# K32W041AM register map
Vendor: nxp.com; File version: 1.0
CPU: CM4 r0p1, little endian, MPU, no FPU, VTOR, 3 interrupt priority bits
Registers are 32-bit, read-write, reset 0x0 unless marked. A register's access mark holds for its fields unless they carry their own. Offsets are from the block's base; [hi:lo] are bit positions.

## WWDT — This is the description of component wwdt It is an Windowed Watchdog Timer with APB bus interface. More details will follow.
Base 0x4000A000
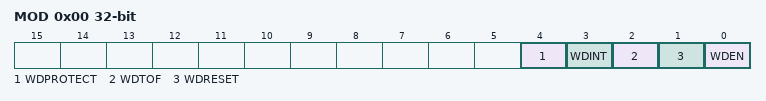
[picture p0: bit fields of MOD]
0x00 MOD — Watchdog mode register. This register contains the basic mode and status of the Watchdog Timer.
  [4] WDPROTECT — Watchdog update mode. This bit can be set once by software and is only cleared by a reset. 0: Flexible. A feed sequence can be performed at any time; ie. the watchdog timer can be reloaded with time-out value (TC) at any time. 1: Threshold. A feed sequence can be performed only after the counter is below the value of WDWARNINT and WDWINDOW; ie. the watchdog timer can be reloaded with time-out value (TC) only when the counter timer value is below the value of WDWARNINT and WDWINDOW, otherwise a 'feed error' is created.
  [3] WDINT — Warning interrupt flag. Set when the timer reaches the value in WDWARNINT. Cleared by software writing a 1 to this bit position. Note that this bit cannot be cleared while the WARNINT value is equal to the value of the TV register. This can occur if the value of WARNINT is 0 and the WDRESET bit is 0 when TV decrements to 0.
  [2] WDTOF — Watchdog time-out flag. Set when the watchdog timer times out, by a feed error, or by events associated with WDPROTECT. Cleared by software writing a 0 to this bit position. Causes a chip reset if WDRESET = 1.
  [1] WDRESET — Watchdog reset enable bit. Once this bit has been written with a 1 it cannot be re-written with a 0. 0: Interrupt. A watchdog time-out will not cause a chip reset. It will cause an interrupt of the watchdog. 1: Reset. A watchdog time-out will cause a chip reset.
  [0] WDEN — Watchdog enable bit. Once this bit is set to one and a watchdog feed is performed, the watchdog timer will run permanently. 0: The watchdog timer is stopped. 1: The watchdog timer is running.
0x04 TC reset 0xFF — Watchdog timer constant register. This 24-bit register determines the time-out value.
  [23:0] COUNT — Watchdog time-out value. If MOD.WDPROTECT is set then changing this value may cause an error.
0x08 FEED wo reset not defined — Watchdog feed sequence register. Writing 0xAA followed by 0x55 to this register reloads the Watchdog timer with the value contained in TC.
  [7:0] FEED — Feed value should be 0xAA followed by 0x55. Writing 0xAA followed by 0x55 to this register will reload the Watchdog timer with the TC value. This operation will also start the Watchdog if it is enabled via the WDMOD register. Setting the WDEN bit in the WDMOD register is not sufficient to enable the Watchdog. A valid feed sequence must be completed after setting WDEN before the Watchdog is capable of generating a reset. Until then, the Watchdog will ignore feed errors.
0x0C TV ro reset 0xFF — Watchdog timer value register. This 24-bit register reads out the current value of the Watchdog timer.
  [23:0] COUNT — Counter timer value. The TV register is used to read the current value of Watchdog timer counter.
0x14 WARNINT — Watchdog Warning Interrupt compare value.
  [9:0] WARNINT — Watchdog warning interrupt compare value.A match of the watchdog timer counter to WARNINT occurs when the bottom 10 bits of the counter have the same value as the 10 bits of WARNINT, and the remaining upper bits of the counter are all 0. This gives a maximum time of 1,023 watchdog timer counts (4,096 watchdog clocks) for the interrupt to occur prior to a watchdog event. If WARNINT is 0, the interrupt will occur at the same time as the watchdog event.
0x18 WINDOW reset 0xFFFFFF — Watchdog Window compare value.
  [23:0] WINDOW — Watchdog window value. The WINDOW register determines the highest TV value allowed when a watchdog feed is performed. If a feed sequence occurs when TV is greater than the value in WINDOW, a watchdog event will occur
